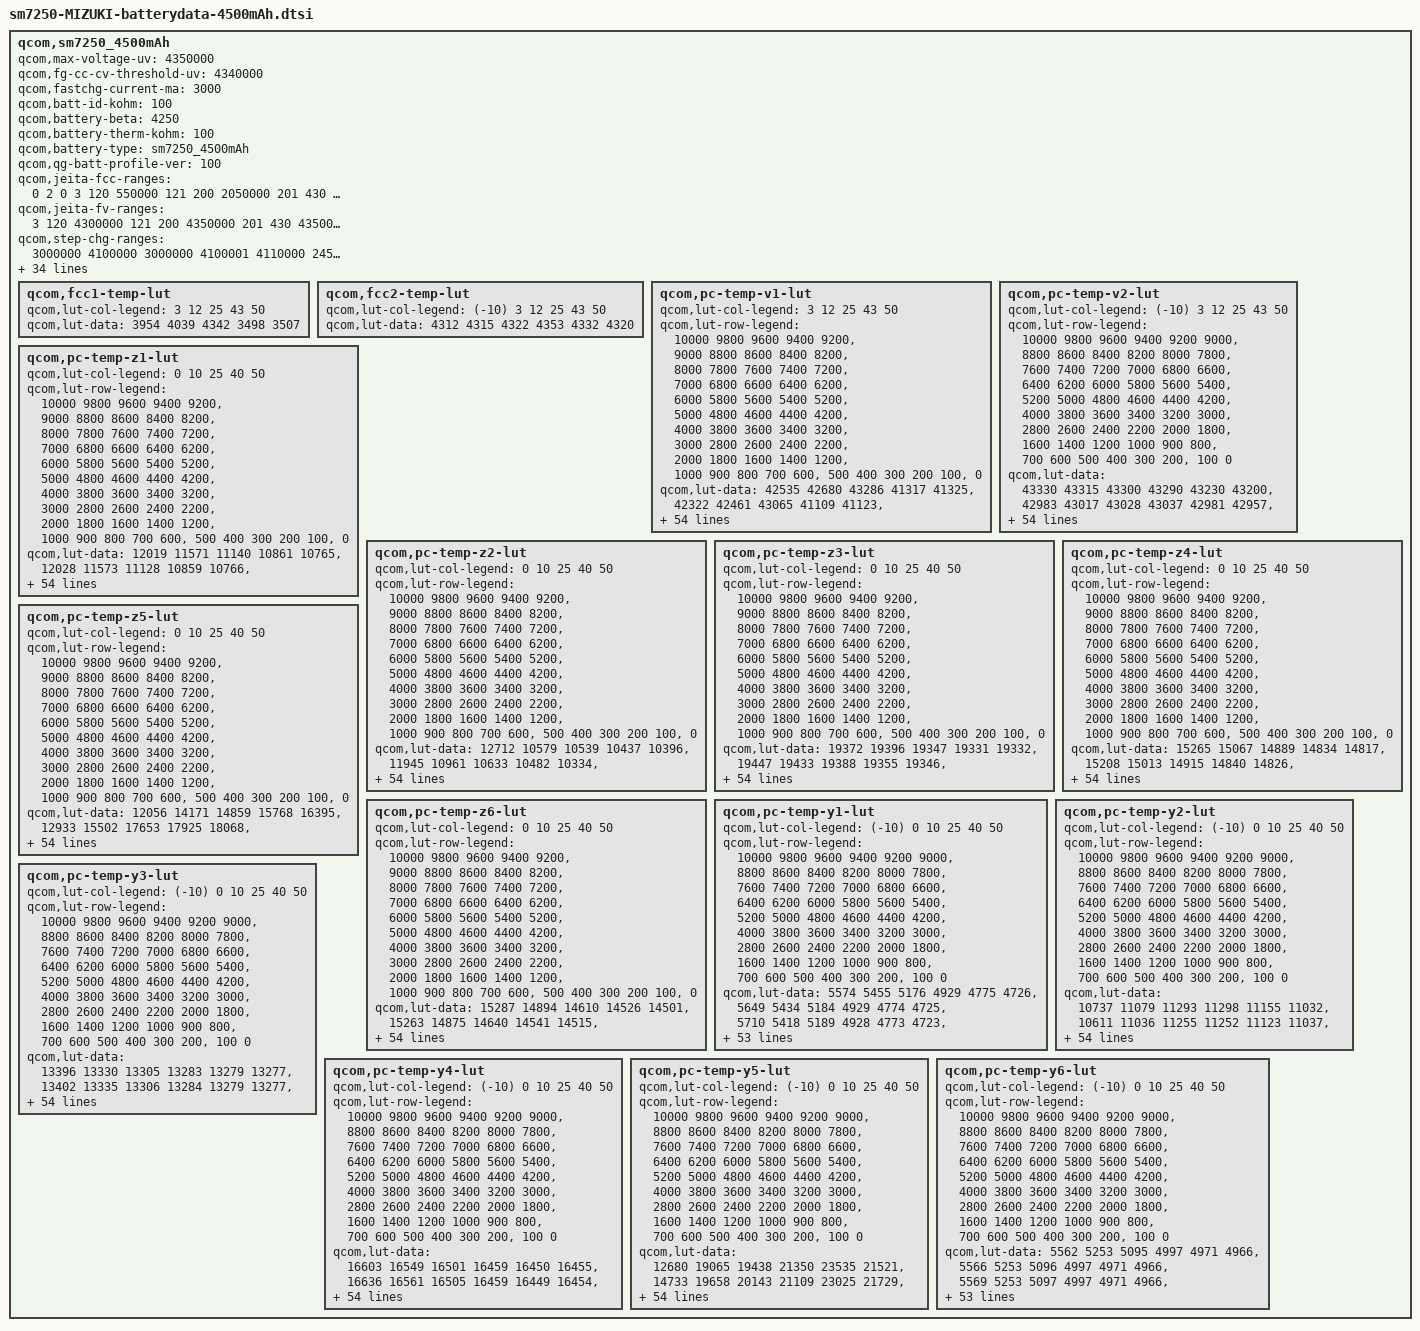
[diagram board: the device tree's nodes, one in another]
/*
 * This software is contributed or developed by KYOCERA Corporation.
 * (C) 2020 KYOCERA Corporation
 *
 * This program is free software; you can redistribute it and/or modify
 * it under the terms of the GNU General Public License version 2 and
 * only version 2 as published by the Free Software Foundation.
 *
 * This program is distributed in the hope that it will be useful,
 * but WITHOUT ANY WARRANTY; without even the implied warranty of
 * MERCHANTABILITY or FITNESS FOR A PARTICULAR PURPOSE.  See the
 * GNU General Public License for more details.
 */

qcom,sm7250_4500mAh {
	qcom,max-voltage-uv = <4350000>;
	qcom,fg-cc-cv-threshold-uv = <4340000>;
	qcom,fastchg-current-ma = <3000>;
	qcom,batt-id-kohm = <100>;
	qcom,battery-beta = <4250>;
	qcom,battery-therm-kohm = <100>;
	qcom,battery-type = "sm7250_4500mAh";
	qcom,qg-batt-profile-ver = <100>;

	qcom,jeita-fcc-ranges = <0   2  0
				  3 120  550000
				121 200  2050000
				201 430  4200000
				431 500  2050000
				500 600  0>;

	qcom,jeita-fv-ranges = <3  120  4300000
				121 200  4350000
				201 430  4350000
				431 500  4150000>;

	qcom,step-chg-ranges = <3000000  4100000  3000000
				4100001  4110000  2450000
				4110001  4120000  2450000
				4120001  4130000  2450000
				4130001  4140000  2450000
				4140001  4150000  2450000
				4150001  4350000  1200000>;
	qcom,step-chg-ranges-cool = <3000000  4350000  500000>;
	qcom,step-chg-ranges-weekcool = <3000000  4100000  2050000
				4100001  4150000  1650000
				4150001  4350000  1200000>;
	qcom,step-chg-ranges-normal = <3000000  4150000  3000000
				4150001  4250000  2450000
				4250001  4350000  1200000>;
	qcom,step-chg-ranges-warm = <3000000  4350000  2050000>;
	qcom,step-chg-temp-thresh = <30 100 200 430>;
	qcom,ocv-based-step-chg;

	/* COOL = 12 DegC, WARM = 43 DegC */
	qcom,jeita-soft-thresholds = <0x4A2A 0x22B8>;
	/* COLD = 3 DegC, HOT = 50 DegC */
	qcom,jeita-hard-thresholds = <0x5571 0x1C22>;
	/* COOL hys = 14 DegC, WARM hys = 41 DegC */
	qcom,jeita-soft-hys-thresholds = <0x477C 0x24CF>;
	qcom,jeita-soft-fcc-ua = <560000 2050000>;
	qcom,jeita-soft-fv-uv = <4300000 4150000>;

	oem,batt-capacity-mah = <4500>;
	oem,deterioration-thresh-good = <75>;
	oem,deterioration-thresh-norm = <50>;
	oem,deterioration-thresh-normtogood = <85>;
	oem,deterioration-thresh-deadtonorm = <60>;
	oem,cycle-count-thresh = <50 100 200 400 600>;
	oem,cycle-count-voltage-comp-mv = <40 80 120 160 200>;
	oem,cont-chg-thresh = <520000 840000 1200000 2200000 3300000>;
	oem,cont-chg-voltage-comp-mv = <40 80 120 160 200>;
	oem,batt-temp-thresh = <(-1250) 300 320 340 360 380 400 420 440 460>;
	oem,cont-chg-factor = <29 42 60 86 124 180 261 378 549 783>;
	oem,cont-chg-factor-batt-care = <15 21 30 43 62 90 131 189 275 392>;
	oem,batt-care-max-voltage-uv = <4200000>;

	qcom,fcc1-temp-lut {
		qcom,lut-col-legend = <3 12 25 43 50>;
		qcom,lut-data = <3954 4039 4342 3498 3507>;
	};

	qcom,fcc2-temp-lut {
		qcom,lut-col-legend = <(-10) 3 12 25 43 50>;
		qcom,lut-data = <4312 4315 4322 4353 4332 4320>;
	};

	qcom,pc-temp-v1-lut {
		qcom,lut-col-legend = <3 12 25 43 50>;
		qcom,lut-row-legend = <10000 9800 9600 9400 9200>,
			<9000 8800 8600 8400 8200>,
			<8000 7800 7600 7400 7200>,
			<7000 6800 6600 6400 6200>,
			<6000 5800 5600 5400 5200>,
			<5000 4800 4600 4400 4200>,
			<4000 3800 3600 3400 3200>,
			<3000 2800 2600 2400 2200>,
			<2000 1800 1600 1400 1200>,
			<1000 900 800 700 600>,
			<500 400 300 200 100>,
			<0>;
		qcom,lut-data = <42535 42680 43286 41317 41325>,
			<42322 42461 43065 41109 41123>,
			<42100 42242 42845 40894 40913>,
			<41869 42021 42626 40675 40696>,
			<41647 41799 42408 40456 40479>,
			<41441 41582 42190 40239 40263>,
			<41247 41372 41974 40023 40047>,
			<41057 41168 41759 39809 39832>,
			<40871 40970 41548 39596 39618>,
			<40691 40775 41342 39387 39407>,
			<40517 40586 41143 39182 39199>,
			<40350 40405 40949 38981 38996>,
			<40174 40231 40756 38786 38801>,
			<39959 40051 40567 38596 38612>,
			<39718 39843 40384 38413 38429>,
			<39528 39635 40206 38237 38253>,
			<39409 39467 40037 38068 38082>,
			<39305 39346 39882 37907 37918>,
			<39159 39217 39742 37760 37768>,
			<38950 39006 39580 37601 37609>,
			<38737 38716 39348 37389 37403>,
			<38562 38506 39101 37144 37160>,
			<38402 38403 38936 36959 36970>,
			<38290 38325 38823 36829 36838>,
			<38230 38241 38723 36719 36726>,
			<38186 38155 38621 36615 36620>,
			<38136 38073 38524 36519 36521>,
			<38077 37999 38438 36432 36431>,
			<38018 37929 38362 36354 36350>,
			<37963 37866 38294 36282 36275>,
			<37912 37810 38233 36215 36205>,
			<37865 37759 38178 36152 36138>,
			<37822 37716 38128 36094 36076>,
			<37783 37680 38084 36041 36015>,
			<37746 37646 38044 35991 35958>,
			<37713 37613 38004 35940 35898>,
			<37678 37581 37966 35889 35838>,
			<37626 37537 37921 35830 35770>,
			<37545 37458 37851 35751 35686>,
			<37446 37357 37757 35652 35585>,
			<37336 37249 37654 35545 35475>,
			<37205 37128 37535 35428 35353>,
			<37054 36987 37399 35296 35217>,
			<36900 36826 37238 35140 35056>,
			<36804 36695 37117 35030 34959>,
			<36721 36628 37046 34968 34906>,
			<36694 36605 37026 34945 34885>,
			<36670 36589 37008 34929 34869>,
			<36642 36572 36987 34910 34847>,
			<36562 36501 36915 34822 34746>,
			<36306 36236 36629 34500 34406>,
			<35850 35786 36179 34054 33964>,
			<35277 35214 35607 33483 33392>,
			<34511 34446 34834 32709 32618>,
			<33287 33229 33628 31513 31421>,
			<30000 30000 30000 30000 30000>;
	};

	qcom,pc-temp-v2-lut {
		qcom,lut-col-legend = <(-10) 3 12 25 43 50>;
		qcom,lut-row-legend = <10000 9800 9600 9400 9200 9000>,
			<8800 8600 8400 8200 8000 7800>,
			<7600 7400 7200 7000 6800 6600>,
			<6400 6200 6000 5800 5600 5400>,
			<5200 5000 4800 4600 4400 4200>,
			<4000 3800 3600 3400 3200 3000>,
			<2800 2600 2400 2200 2000 1800>,
			<1600 1400 1200 1000 900 800>,
			<700 600 500 400 300 200>,
			<100 0>;
		qcom,lut-data = <43330 43315 43300 43290 43230 43200>,
			<42983 43017 43028 43037 42981 42957>,
			<42667 42739 42769 42794 42740 42722>,
			<42386 42483 42526 42559 42508 42493>,
			<42138 42248 42300 42335 42286 42272>,
			<41905 42026 42081 42115 42068 42055>,
			<41664 41808 41864 41896 41851 41839>,
			<41428 41597 41652 41681 41637 41624>,
			<41229 41392 41444 41469 41426 41414>,
			<41085 41188 41236 41258 41218 41206>,
			<40947 40990 41033 41053 41014 41002>,
			<40762 40800 40846 40858 40817 40805>,
			<40524 40620 40674 40672 40625 40612>,
			<40275 40434 40492 40486 40438 40426>,
			<40025 40228 40275 40290 40255 40245>,
			<39774 40013 40048 40098 40078 40070>,
			<39551 39808 39863 39929 39912 39904>,
			<39354 39612 39718 39786 39765 39754>,
			<39170 39419 39569 39630 39608 39596>,
			<38992 39218 39363 39425 39405 39397>,
			<38822 39015 39119 39194 39172 39169>,
			<38668 38837 38916 38993 38972 38971>,
			<38524 38689 38760 38817 38806 38807>,
			<38399 38558 38627 38663 38661 38662>,
			<38308 38441 38511 38540 38540 38541>,
			<38237 38337 38408 38436 38437 38435>,
			<38177 38243 38315 38343 38343 38340>,
			<38120 38154 38227 38257 38254 38250>,
			<38067 38073 38146 38179 38172 38167>,
			<38019 38011 38071 38104 38099 38092>,
			<37974 37962 38001 38035 38034 38026>,
			<37931 37920 37939 37969 37970 37962>,
			<37888 37886 37888 37909 37907 37898>,
			<37846 37856 37845 37852 37844 37834>,
			<37802 37825 37803 37793 37771 37758>,
			<37759 37793 37763 37732 37682 37653>,
			<37713 37756 37721 37667 37588 37540>,
			<37658 37710 37668 37596 37504 37446>,
			<37590 37648 37600 37518 37425 37365>,
			<37510 37572 37520 37434 37342 37283>,
			<37410 37464 37421 37345 37254 37194>,
			<37291 37326 37305 37246 37159 37098>,
			<37175 37190 37182 37125 37046 36989>,
			<37062 37045 37039 36989 36906 36853>,
			<36966 36941 36948 36913 36836 36777>,
			<36894 36883 36903 36868 36808 36752>,
			<36854 36853 36880 36854 36792 36737>,
			<36808 36822 36858 36838 36776 36719>,
			<36738 36770 36818 36806 36741 36681>,
			<36584 36643 36710 36710 36609 36536>,
			<36286 36360 36406 36392 36271 36165>,
			<35832 35892 35901 35911 35780 35674>,
			<35222 35255 35254 35291 35149 35039>,
			<34365 34370 34366 34451 34296 34185>,
			<32940 32942 33061 33250 33114 32963>,
			<29519 29510 29510 29509 30000 30000>;
	};

	qcom,pc-temp-z1-lut {
		qcom,lut-col-legend = <0 10 25 40 50>;
		qcom,lut-row-legend = <10000 9800 9600 9400 9200>,
			<9000 8800 8600 8400 8200>,
			<8000 7800 7600 7400 7200>,
			<7000 6800 6600 6400 6200>,
			<6000 5800 5600 5400 5200>,
			<5000 4800 4600 4400 4200>,
			<4000 3800 3600 3400 3200>,
			<3000 2800 2600 2400 2200>,
			<2000 1800 1600 1400 1200>,
			<1000 900 800 700 600>,
			<500 400 300 200 100>,
			<0>;
		qcom,lut-data = <12019 11571 11140 10861 10765>,
			<12028 11573 11128 10859 10766>,
			<12010 11574 11115 10854 10764>,
			<11978 11571 11102 10846 10761>,
			<11952 11558 11092 10839 10758>,
			<11939 11542 11084 10835 10756>,
			<11930 11523 11077 10831 10753>,
			<11924 11503 11072 10828 10751>,
			<11920 11491 11067 10827 10749>,
			<11917 11485 11064 10825 10748>,
			<11913 11481 11063 10823 10747>,
			<11900 11475 11061 10822 10746>,
			<11886 11468 11057 10822 10745>,
			<11872 11463 11053 10821 10745>,
			<11857 11459 11051 10821 10745>,
			<11850 11455 11052 10822 10745>,
			<11852 11455 11052 10823 10746>,
			<11857 11467 11053 10824 10746>,
			<11862 11479 11055 10825 10747>,
			<11878 11484 11056 10826 10748>,
			<11891 11489 11057 10827 10749>,
			<11886 11491 11059 10829 10750>,
			<11867 11483 11061 10830 10752>,
			<11856 11472 11068 10833 10754>,
			<11859 11472 11075 10835 10757>,
			<11864 11482 11082 10839 10760>,
			<11865 11493 11089 10842 10763>,
			<11861 11494 11093 10845 10766>,
			<11857 11495 11096 10848 10769>,
			<11859 11495 11099 10850 10771>,
			<11867 11498 11104 10853 10773>,
			<11876 11503 11110 10856 10776>,
			<11881 11509 11117 10859 10778>,
			<11887 11522 11124 10863 10781>,
			<11891 11533 11130 10867 10785>,
			<11903 11537 11133 10872 10787>,
			<11918 11540 11135 10877 10790>,
			<11923 11541 11137 10881 10793>,
			<11923 11544 11142 10886 10796>,
			<11921 11548 11148 10890 10799>,
			<11918 11549 11155 10894 10802>,
			<11913 11550 11162 10898 10804>,
			<11922 11551 11170 10902 10806>,
			<11941 11556 11178 10906 10808>,
			<11945 11565 11179 10909 10810>,
			<11951 11560 11182 10910 10811>,
			<11925 11559 11181 10912 10812>,
			<11932 11566 11176 10915 10814>,
			<11930 11560 11183 10918 10817>,
			<11935 11559 11187 10922 10822>,
			<11960 11564 11193 10925 10826>,
			<11964 11563 11199 10931 10831>,
			<11971 11592 11217 10938 10837>,
			<11992 11606 11225 10948 10845>,
			<11992 11606 11225 10948 10845>,
			<11992 11606 11225 10948 10845>;
	};

	qcom,pc-temp-z2-lut {
		qcom,lut-col-legend = <0 10 25 40 50>;
		qcom,lut-row-legend = <10000 9800 9600 9400 9200>,
			<9000 8800 8600 8400 8200>,
			<8000 7800 7600 7400 7200>,
			<7000 6800 6600 6400 6200>,
			<6000 5800 5600 5400 5200>,
			<5000 4800 4600 4400 4200>,
			<4000 3800 3600 3400 3200>,
			<3000 2800 2600 2400 2200>,
			<2000 1800 1600 1400 1200>,
			<1000 900 800 700 600>,
			<500 400 300 200 100>,
			<0>;
		qcom,lut-data = <12712 10579 10539 10437 10396>,
			<11945 10961 10633 10482 10334>,
			<11307 11143 10622 10469 10314>,
			<10707 11061 10602 10446 10300>,
			<10388 10723 10573 10416 10288>,
			<10357 10503 10524 10363 10258>,
			<10341 10478 10496 10316 10228>,
			<10331 10460 10498 10296 10227>,
			<10322 10455 10505 10282 10239>,
			<10316 10465 10506 10277 10252>,
			<10335 10480 10505 10285 10263>,
			<10425 10555 10503 10294 10273>,
			<10496 10752 10497 10303 10281>,
			<10476 10856 10489 10312 10290>,
			<10423 10735 10485 10317 10298>,
			<10398 10553 10488 10320 10310>,
			<10393 10510 10494 10324 10326>,
			<10388 10517 10503 10331 10337>,
			<10388 10526 10522 10357 10345>,
			<10395 10537 10545 10389 10356>,
			<10402 10553 10580 10446 10409>,
			<10403 10561 10614 10525 10511>,
			<10402 10556 10622 10552 10548>,
			<10402 10548 10619 10558 10487>,
			<10410 10547 10611 10552 10393>,
			<10425 10554 10598 10497 10310>,
			<10435 10559 10575 10377 10221>,
			<10441 10549 10549 10281 10174>,
			<10445 10524 10514 10214 10157>,
			<10448 10513 10488 10168 10144>,
			<10450 10521 10490 10168 10146>,
			<10452 10535 10505 10200 10166>,
			<10457 10551 10525 10237 10193>,
			<10464 10570 10557 10272 10234>,
			<10471 10586 10595 10310 10292>,
			<10477 10596 10620 10350 10344>,
			<10483 10604 10640 10392 10394>,
			<10491 10615 10661 10436 10433>,
			<10501 10643 10696 10491 10454>,
			<10507 10669 10736 10548 10471>,
			<10501 10670 10744 10563 10474>,
			<10488 10659 10725 10530 10451>,
			<10489 10658 10718 10504 10429>,
			<10536 10673 10728 10492 10420>,
			<14837 10777 10734 10461 10397>,
			<16165 10769 10706 10489 10353>,
			<20813 10765 10705 10499 10370>,
			<19221 10777 10695 10512 10391>,
			<19301 10836 10708 10603 10483>,
			<20631 10928 10747 10632 10516>,
			<19576 11039 10691 10375 10260>,
			<18100 11075 10602 10301 10183>,
			<15575 11073 10527 10258 10149>,
			<14743 11024 10476 10202 10085>,
			<14743 11024 10476 10202 10085>,
			<14743 11024 10476 10202 10085>;
	};

	qcom,pc-temp-z3-lut {
		qcom,lut-col-legend = <0 10 25 40 50>;
		qcom,lut-row-legend = <10000 9800 9600 9400 9200>,
			<9000 8800 8600 8400 8200>,
			<8000 7800 7600 7400 7200>,
			<7000 6800 6600 6400 6200>,
			<6000 5800 5600 5400 5200>,
			<5000 4800 4600 4400 4200>,
			<4000 3800 3600 3400 3200>,
			<3000 2800 2600 2400 2200>,
			<2000 1800 1600 1400 1200>,
			<1000 900 800 700 600>,
			<500 400 300 200 100>,
			<0>;
		qcom,lut-data = <19372 19396 19347 19331 19332>,
			<19447 19433 19388 19355 19346>,
			<19512 19460 19402 19369 19358>,
			<19576 19476 19410 19379 19368>,
			<19608 19490 19413 19382 19372>,
			<19609 19497 19415 19382 19371>,
			<19609 19497 19416 19381 19371>,
			<19609 19496 19414 19378 19370>,
			<19606 19495 19409 19374 19368>,
			<19603 19491 19404 19370 19366>,
			<19600 19486 19399 19367 19364>,
			<19597 19484 19394 19364 19363>,
			<19594 19482 19391 19362 19360>,
			<19591 19480 19389 19361 19356>,
			<19586 19477 19387 19359 19352>,
			<19581 19471 19385 19357 19350>,
			<19570 19467 19384 19355 19347>,
			<19559 19461 19382 19352 19345>,
			<19558 19457 19378 19348 19341>,
			<19571 19459 19377 19345 19338>,
			<19583 19468 19379 19347 19340>,
			<19582 19472 19383 19354 19346>,
			<19575 19464 19384 19362 19355>,
			<19569 19453 19384 19381 19372>,
			<19563 19453 19384 19398 19389>,
			<19558 19471 19396 19399 19390>,
			<19557 19487 19420 19396 19387>,
			<19562 19489 19428 19392 19382>,
			<19568 19490 19424 19386 19376>,
			<19568 19490 19418 19378 19369>,
			<19568 19486 19413 19372 19363>,
			<19566 19479 19406 19368 19358>,
			<19563 19473 19400 19363 19353>,
			<19558 19468 19395 19358 19348>,
			<19554 19463 19389 19352 19342>,
			<19551 19460 19385 19348 19339>,
			<19548 19456 19382 19345 19337>,
			<19544 19453 19379 19343 19335>,
			<19539 19450 19376 19345 19337>,
			<19535 19447 19373 19349 19341>,
			<19532 19443 19372 19351 19345>,
			<19529 19439 19371 19352 19347>,
			<19524 19436 19370 19353 19349>,
			<19511 19431 19370 19354 19352>,
			<19262 19414 19360 19350 19348>,
			<19257 19400 19352 19334 19339>,
			<19256 19399 19346 19332 19331>,
			<19257 19388 19345 19329 19326>,
			<19256 19362 19343 19318 19314>,
			<19256 19352 19339 19319 19316>,
			<19256 19345 19352 19348 19340>,
			<19256 19332 19363 19351 19341>,
			<19257 19330 19361 19350 19341>,
			<19257 19328 19363 19354 19347>,
			<19257 19328 19363 19354 19347>,
			<19257 19328 19363 19354 19347>;
	};

	qcom,pc-temp-z4-lut {
		qcom,lut-col-legend = <0 10 25 40 50>;
		qcom,lut-row-legend = <10000 9800 9600 9400 9200>,
			<9000 8800 8600 8400 8200>,
			<8000 7800 7600 7400 7200>,
			<7000 6800 6600 6400 6200>,
			<6000 5800 5600 5400 5200>,
			<5000 4800 4600 4400 4200>,
			<4000 3800 3600 3400 3200>,
			<3000 2800 2600 2400 2200>,
			<2000 1800 1600 1400 1200>,
			<1000 900 800 700 600>,
			<500 400 300 200 100>,
			<0>;
		qcom,lut-data = <15265 15067 14889 14834 14817>,
			<15208 15013 14915 14840 14826>,
			<15142 14963 14883 14828 14818>,
			<15067 14918 14834 14796 14792>,
			<15000 14874 14801 14769 14766>,
			<14946 14837 14774 14745 14742>,
			<14900 14806 14752 14726 14723>,
			<14863 14779 14735 14718 14715>,
			<14834 14760 14721 14713 14711>,
			<14809 14745 14714 14708 14707>,
			<14779 14732 14709 14704 14703>,
			<14742 14717 14705 14699 14699>,
			<14720 14699 14701 14693 14696>,
			<14734 14690 14696 14688 14692>,
			<14769 14702 14691 14683 14688>,
			<14786 14721 14685 14677 14684>,
			<14765 14723 14681 14673 14680>,
			<14735 14708 14679 14672 14678>,
			<14732 14694 14678 14672 14676>,
			<14774 14729 14678 14673 14675>,
			<14826 14833 14733 14703 14698>,
			<14867 14887 14811 14771 14759>,
			<14907 14880 14826 14793 14783>,
			<14926 14865 14816 14764 14755>,
			<14910 14844 14800 14728 14718>,
			<14876 14810 14772 14713 14704>,
			<14849 14779 14735 14703 14697>,
			<14826 14763 14717 14697 14691>,
			<14806 14751 14711 14693 14687>,
			<14792 14746 14707 14689 14683>,
			<14782 14745 14705 14685 14679>,
			<14774 14744 14703 14681 14674>,
			<14769 14743 14702 14679 14671>,
			<14765 14741 14701 14678 14670>,
			<14761 14738 14701 14678 14669>,
			<14756 14733 14700 14678 14669>,
			<14751 14727 14699 14679 14671>,
			<14748 14725 14698 14679 14674>,
			<14747 14727 14701 14682 14678>,
			<14745 14729 14705 14688 14682>,
			<14739 14725 14705 14689 14683>,
			<14727 14711 14695 14681 14677>,
			<14716 14702 14689 14677 14675>,
			<14710 14696 14688 14682 14687>,
			<14900 14673 14674 14666 14668>,
			<14893 14666 14666 14660 14648>,
			<14886 14655 14658 14652 14642>,
			<14879 14658 14641 14638 14631>,
			<14872 14677 14632 14631 14625>,
			<14871 14690 14641 14630 14623>,
			<14878 14712 14651 14641 14651>,
			<14883 14730 14644 14645 14655>,
			<14886 14733 14648 14648 14657>,
			<14887 14736 14649 14646 14654>,
			<14887 14736 14649 14646 14654>,
			<14887 14736 14649 14646 14654>;
	};

	qcom,pc-temp-z5-lut {
		qcom,lut-col-legend = <0 10 25 40 50>;
		qcom,lut-row-legend = <10000 9800 9600 9400 9200>,
			<9000 8800 8600 8400 8200>,
			<8000 7800 7600 7400 7200>,
			<7000 6800 6600 6400 6200>,
			<6000 5800 5600 5400 5200>,
			<5000 4800 4600 4400 4200>,
			<4000 3800 3600 3400 3200>,
			<3000 2800 2600 2400 2200>,
			<2000 1800 1600 1400 1200>,
			<1000 900 800 700 600>,
			<500 400 300 200 100>,
			<0>;
		qcom,lut-data = <12056 14171 14859 15768 16395>,
			<12933 15502 17653 17925 18068>,
			<14571 16779 18626 19276 19486>,
			<17239 18056 19284 20376 20748>,
			<19542 19813 20032 21313 21855>,
			<20766 21381 20752 22203 22841>,
			<21699 22540 21509 22827 23695>,
			<22732 23675 22605 23034 24383>,
			<23915 24960 23675 23153 24950>,
			<25169 26494 23917 23241 25534>,
			<26555 28045 23779 23487 26338>,
			<28243 29540 23682 23875 27110>,
			<29812 31112 24056 24404 27358>,
			<31115 31824 24996 25469 27394>,
			<32308 31108 25943 26646 27462>,
			<32747 29967 26886 27915 28241>,
			<31617 29805 27913 29094 29661>,
			<29984 31316 29135 29404 30166>,
			<31141 33481 30587 29354 30198>,
			<43044 35757 31238 29192 30161>,
			<54122 38424 29721 27594 28651>,
			<52513 39538 26786 24213 24768>,
			<44135 33359 23901 22893 23108>,
			<36892 24464 20384 23131 23692>,
			<32648 22682 18301 23635 24737>,
			<29402 24821 20602 24714 26158>,
			<28683 27821 25944 26785 28378>,
			<30126 31049 29605 27813 29457>,
			<32368 34860 31715 27689 29246>,
			<34658 37732 33407 27491 28938>,
			<37478 39903 34929 27935 29087>,
			<39712 41521 36281 29549 30235>,
			<41004 42074 37299 30801 31285>,
			<42023 42306 38153 31230 31752>,
			<42495 42319 38749 31503 32076>,
			<42637 41928 38626 31473 32103>,
			<42589 41084 37413 30892 31703>,
			<42152 40031 35731 30309 31144>,
			<40884 38400 33043 30021 30533>,
			<39513 36587 29699 29753 29855>,
			<38644 35243 28250 29674 29744>,
			<37852 34076 27835 29700 31496>,
			<36811 32847 27354 29696 33046>,
			<34593 31220 26645 29259 33840>,
			<12048 32945 25469 28215 33611>,
			<11608 28165 23302 21273 26855>,
			<11518 28971 22219 21244 23351>,
			<11473 25999 25432 22870 24476>,
			<11479 18285 27457 21754 23030>,
			<11529 16641 22781 22801 25962>,
			<11552 15431 22040 28902 26677>,
			<11506 14080 24914 26203 22698>,
			<11450 13840 22965 23076 20330>,
			<11406 13673 22300 22173 19429>,
			<11406 13673 22300 22173 19429>,
			<11406 13673 22300 22173 19429>;
	};

	qcom,pc-temp-z6-lut {
		qcom,lut-col-legend = <0 10 25 40 50>;
		qcom,lut-row-legend = <10000 9800 9600 9400 9200>,
			<9000 8800 8600 8400 8200>,
			<8000 7800 7600 7400 7200>,
			<7000 6800 6600 6400 6200>,
			<6000 5800 5600 5400 5200>,
			<5000 4800 4600 4400 4200>,
			<4000 3800 3600 3400 3200>,
			<3000 2800 2600 2400 2200>,
			<2000 1800 1600 1400 1200>,
			<1000 900 800 700 600>,
			<500 400 300 200 100>,
			<0>;
		qcom,lut-data = <15287 14894 14610 14526 14501>,
			<15263 14875 14640 14541 14515>,
			<15235 14855 14629 14538 14514>,
			<15201 14836 14613 14530 14509>,
			<15165 14813 14599 14522 14502>,
			<15128 14791 14586 14511 14492>,
			<15088 14771 14575 14501 14483>,
			<15055 14753 14564 14495 14478>,
			<15029 14738 14555 14490 14475>,
			<15006 14727 14548 14486 14472>,
			<14980 14718 14543 14482 14469>,
			<14948 14706 14539 14478 14466>,
			<14929 14694 14534 14474 14462>,
			<14930 14688 14530 14471 14459>,
			<14935 14690 14526 14468 14455>,
			<14936 14692 14523 14465 14451>,
			<14925 14692 14520 14462 14449>,
			<14909 14685 14518 14459 14446>,
			<14908 14678 14516 14457 14443>,
			<14934 14695 14516 14456 14441>,
			<14964 14744 14541 14471 14453>,
			<14982 14769 14578 14505 14484>,
			<14996 14763 14585 14517 14497>,
			<15002 14751 14581 14515 14495>,
			<14994 14744 14577 14511 14491>,
			<14978 14740 14574 14507 14487>,
			<14967 14737 14572 14503 14482>,
			<14959 14734 14569 14498 14478>,
			<14954 14731 14566 14492 14473>,
			<14950 14729 14562 14487 14468>,
			<14948 14727 14559 14483 14463>,
			<14946 14725 14555 14479 14459>,
			<14944 14724 14552 14476 14455>,
			<14943 14724 14550 14473 14451>,
			<14942 14723 14548 14470 14448>,
			<14943 14721 14547 14468 14447>,
			<14945 14720 14545 14467 14447>,
			<14948 14720 14544 14467 14447>,
			<14953 14723 14545 14469 14449>,
			<14958 14726 14547 14474 14453>,
			<14960 14725 14547 14476 14455>,
			<14961 14721 14544 14474 14455>,
			<14963 14719 14542 14473 14455>,
			<14964 14719 14544 14477 14462>,
			<14935 14707 14535 14469 14453>,
			<14933 14697 14527 14458 14439>,
			<14931 14694 14521 14453 14433>,
			<14930 14690 14514 14446 14425>,
			<14930 14688 14510 14438 14417>,
			<14935 14693 14512 14438 14417>,
			<14946 14704 14526 14460 14444>,
			<14955 14710 14531 14465 14449>,
			<14966 14717 14535 14468 14452>,
			<14980 14725 14540 14472 14456>,
			<14980 14725 14540 14472 14456>,
			<14980 14725 14540 14472 14456>;
	};

	qcom,pc-temp-y1-lut {
		qcom,lut-col-legend = <(-10) 0 10 25 40 50>;
		qcom,lut-row-legend = <10000 9800 9600 9400 9200 9000>,
			<8800 8600 8400 8200 8000 7800>,
			<7600 7400 7200 7000 6800 6600>,
			<6400 6200 6000 5800 5600 5400>,
			<5200 5000 4800 4600 4400 4200>,
			<4000 3800 3600 3400 3200 3000>,
			<2800 2600 2400 2200 2000 1800>,
			<1600 1400 1200 1000 900 800>,
			<700 600 500 400 300 200>,
			<100 0>;
		qcom,lut-data = <5574 5455 5176 4929 4775 4726>,
			<5649 5434 5184 4929 4774 4725>,
			<5710 5418 5189 4928 4773 4723>,
			<5756 5405 5191 4926 4773 4722>,
			<5786 5397 5192 4924 4772 4720>,
			<5798 5392 5190 4922 4771 4719>,
			<5787 5394 5186 4920 4770 4718>,
			<5758 5402 5179 4917 4769 4717>,
			<5746 5406 5176 4915 4768 4717>,
			<5763 5400 5174 4913 4767 4716>,
			<5783 5393 5171 4910 4766 4716>,
			<5785 5396 5167 4908 4765 4716>,
			<5776 5407 5158 4906 4764 4716>,
			<5771 5415 5153 4905 4763 4716>,
			<5779 5409 5157 4906 4763 4716>,
			<5795 5398 5163 4906 4764 4716>,
			<5798 5394 5164 4906 4764 4716>,
			<5782 5394 5158 4905 4763 4716>,
			<5768 5395 5152 4903 4763 4716>,
			<5769 5395 5154 4904 4764 4716>,
			<5775 5394 5158 4907 4765 4717>,
			<5778 5394 5160 4908 4766 4717>,
			<5783 5393 5161 4909 4767 4718>,
			<5789 5393 5162 4911 4767 4720>,
			<5785 5395 5161 4914 4768 4721>,
			<5764 5405 5158 4917 4770 4722>,
			<5748 5412 5156 4920 4773 4723>,
			<5751 5405 5157 4923 4775 4725>,
			<5756 5392 5160 4926 4777 4726>,
			<5762 5388 5163 4929 4779 4728>,
			<5775 5388 5170 4934 4782 4731>,
			<5787 5387 5175 4938 4784 4733>,
			<5782 5392 5174 4940 4787 4735>,
			<5766 5404 5171 4942 4789 4736>,
			<5755 5412 5170 4943 4791 4737>,
			<5749 5417 5171 4945 4794 4739>,
			<5741 5420 5174 4947 4795 4740>,
			<5737 5418 5178 4951 4797 4742>,
			<5734 5405 5184 4956 4798 4743>,
			<5732 5396 5188 4959 4800 4745>,
			<5732 5399 5188 4961 4802 4746>,
			<5732 5406 5186 4963 4804 4747>,
			<5730 5411 5188 4966 4807 4749>,
			<5721 5415 5200 4971 4810 4752>,
			<5717 5414 5207 4978 4813 4754>,
			<5736 5407 5209 4987 4815 4756>,
			<5742 5408 5214 4992 4815 4756>,
			<5740 5410 5226 4993 4815 4755>,
			<5740 5414 5225 4989 4815 4755>,
			<5762 5425 5216 4982 4814 4757>,
			<5769 5410 5221 4982 4817 4758>,
			<5777 5400 5218 4990 4821 4761>,
			<5795 5409 5237 4998 4825 4765>,
			<5838 5429 5236 5007 4831 4769>,
			<5838 5429 5236 5007 4831 4769>,
			<5838 5429 5236 5007 4831 4769>;
	};

	qcom,pc-temp-y2-lut {
		qcom,lut-col-legend = <(-10) 0 10 25 40 50>;
		qcom,lut-row-legend = <10000 9800 9600 9400 9200 9000>,
			<8800 8600 8400 8200 8000 7800>,
			<7600 7400 7200 7000 6800 6600>,
			<6400 6200 6000 5800 5600 5400>,
			<5200 5000 4800 4600 4400 4200>,
			<4000 3800 3600 3400 3200 3000>,
			<2800 2600 2400 2200 2000 1800>,
			<1600 1400 1200 1000 900 800>,
			<700 600 500 400 300 200>,
			<100 0>;
		qcom,lut-data = <10737 11079 11293 11298 11155 11032>,
			<10611 11036 11255 11252 11123 11037>,
			<10533 10994 11217 11202 11091 11032>,
			<10491 10954 11181 11152 11059 11021>,
			<10474 10919 11146 11110 11028 11004>,
			<10470 10892 11113 11079 11000 10983>,
			<10493 10871 11078 11060 10971 10951>,
			<10562 10854 11044 11045 10942 10906>,
			<10631 10845 11022 11036 10925 10881>,
			<10712 10839 11009 11029 10911 10873>,
			<10780 10836 11001 11024 10900 10867>,
			<10793 10864 11005 11023 10895 10857>,
			<10795 10988 11032 11021 10874 10844>,
			<10798 11085 11070 11023 10862 10837>,
			<10829 11111 11150 11040 10865 10840>,
			<10882 11127 11258 11072 10873 10847>,
			<10911 11143 11325 11123 10898 10854>,
			<10926 11160 11373 11223 10990 10864>,
			<10934 11172 11399 11308 11071 10879>,
			<10932 11168 11384 11350 11091 10941>,
			<10918 11158 11345 11380 11103 11064>,
			<10887 11154 11329 11382 11112 11116>,
			<10459 11174 11339 11329 11132 11114>,
			<9906 11202 11355 11278 11153 11111>,
			<9766 11217 11370 11283 11165 11113>,
			<9732 11226 11385 11311 11178 11129>,
			<9715 11236 11401 11347 11193 11148>,
			<9707 11260 11420 11411 11217 11171>,
			<9702 11290 11440 11473 11248 11196>,
			<9698 11301 11454 11491 11277 11217>,
			<9695 11293 11466 11498 11310 11233>,
			<9693 11281 11473 11500 11331 11248>,
			<9690 11265 11471 11497 11324 11265>,
			<9686 11231 11466 11493 11306 11282>,
			<9683 11197 11459 11493 11299 11288>,
			<9681 11168 11443 11494 11294 11261>,
			<9679 11135 11419 11494 11287 11219>,
			<9677 11100 11397 11480 11274 11193>,
			<9675 11062 11373 11446 11247 11173>,
			<9673 11002 11344 11414 11224 11154>,
			<9671 10783 11303 11388 11208 11135>,
			<9669 10404 11246 11361 11193 11116>,
			<9667 10113 11178 11333 11182 11090>,
			<9666 9879 11092 11302 11174 11051>,
			<9665 9760 11013 11243 11127 10983>,
			<9664 9727 10946 11190 10955 10842>,
			<9663 9716 10928 11189 10961 10827>,
			<9663 9708 10915 11194 11006 10829>,
			<9662 9703 10910 11243 11002 10833>,
			<9661 9697 10924 11234 10977 10843>,
			<9661 9691 10883 11169 10943 10835>,
			<9660 9686 10767 11104 10880 10759>,
			<9659 9678 10682 11045 10811 10667>,
			<9655 9673 10632 10956 10664 10542>,
			<9655 9673 10632 10956 10664 10542>,
			<9655 9673 10632 10956 10664 10542>;
	};

	qcom,pc-temp-y3-lut {
		qcom,lut-col-legend = <(-10) 0 10 25 40 50>;
		qcom,lut-row-legend = <10000 9800 9600 9400 9200 9000>,
			<8800 8600 8400 8200 8000 7800>,
			<7600 7400 7200 7000 6800 6600>,
			<6400 6200 6000 5800 5600 5400>,
			<5200 5000 4800 4600 4400 4200>,
			<4000 3800 3600 3400 3200 3000>,
			<2800 2600 2400 2200 2000 1800>,
			<1600 1400 1200 1000 900 800>,
			<700 600 500 400 300 200>,
			<100 0>;
		qcom,lut-data = <13396 13330 13305 13283 13279 13277>,
			<13402 13335 13306 13284 13279 13277>,
			<13409 13340 13307 13285 13279 13277>,
			<13415 13344 13309 13285 13279 13277>,
			<13421 13348 13311 13286 13280 13278>,
			<13426 13352 13313 13286 13280 13278>,
			<13429 13355 13315 13287 13281 13279>,
			<13432 13357 13318 13288 13282 13280>,
			<13433 13359 13320 13289 13283 13281>,
			<13420 13362 13321 13289 13283 13281>,
			<13405 13363 13322 13289 13284 13282>,
			<13404 13363 13325 13290 13284 13282>,
			<13409 13361 13328 13293 13285 13283>,
			<13412 13357 13330 13295 13285 13283>,
			<13409 13354 13325 13296 13285 13283>,
			<13401 13350 13317 13296 13285 13283>,
			<13393 13346 13315 13296 13286 13284>,
			<13386 13342 13316 13297 13288 13285>,
			<13380 13339 13316 13297 13291 13286>,
			<13375 13335 13314 13295 13289 13285>,
			<13370 13331 13309 13291 13283 13282>,
			<13365 13328 13305 13288 13280 13279>,
			<13359 13326 13302 13286 13279 13277>,
			<13351 13324 13300 13284 13278 13276>,
			<13339 13322 13300 13283 13278 13276>,
			<13318 13320 13299 13283 13278 13277>,
			<13306 13318 13299 13283 13278 13277>,
			<13316 13313 13299 13284 13278 13277>,
			<13338 13308 13298 13284 13277 13276>,
			<13355 13307 13297 13284 13277 13276>,
			<13365 13308 13297 13284 13277 13276>,
			<13375 13310 13297 13284 13277 13277>,
			<13384 13312 13297 13283 13278 13277>,
			<13394 13316 13298 13283 13278 13278>,
			<13404 13319 13299 13283 13278 13279>,
			<13419 13321 13299 13283 13277 13278>,
			<13436 13322 13299 13283 13277 13276>,
			<13454 13324 13300 13283 13277 13276>,
			<13472 13326 13300 13282 13278 13277>,
			<13492 13328 13300 13282 13278 13278>,
			<13519 13325 13301 13282 13279 13278>,
			<13551 13320 13301 13282 13280 13279>,
			<13590 13319 13301 13282 13280 13279>,
			<13639 13328 13302 13283 13277 13277>,
			<13697 13342 13304 13284 13277 13277>,
			<13771 13361 13310 13288 13284 13282>,
			<13812 13372 13314 13292 13287 13284>,
			<13867 13387 13320 13295 13289 13286>,
			<13892 13392 13323 13296 13288 13286>,
			<13890 13392 13324 13296 13285 13282>,
			<13933 13396 13322 13292 13284 13281>,
			<13990 13407 13322 13293 13285 13283>,
			<14106 13437 13327 13297 13287 13286>,
			<14468 13483 13338 13302 13292 13292>,
			<14468 13483 13338 13302 13292 13292>,
			<14468 13483 13338 13302 13292 13292>;
	};

	qcom,pc-temp-y4-lut {
		qcom,lut-col-legend = <(-10) 0 10 25 40 50>;
		qcom,lut-row-legend = <10000 9800 9600 9400 9200 9000>,
			<8800 8600 8400 8200 8000 7800>,
			<7600 7400 7200 7000 6800 6600>,
			<6400 6200 6000 5800 5600 5400>,
			<5200 5000 4800 4600 4400 4200>,
			<4000 3800 3600 3400 3200 3000>,
			<2800 2600 2400 2200 2000 1800>,
			<1600 1400 1200 1000 900 800>,
			<700 600 500 400 300 200>,
			<100 0>;
		qcom,lut-data = <16603 16549 16501 16459 16450 16455>,
			<16636 16561 16505 16459 16449 16454>,
			<16670 16572 16509 16460 16449 16454>,
			<16701 16583 16513 16461 16449 16453>,
			<16729 16592 16516 16462 16449 16453>,
			<16751 16601 16519 16463 16450 16453>,
			<16765 16607 16520 16464 16450 16452>,
			<16774 16613 16522 16465 16450 16452>,
			<16794 16619 16523 16467 16451 16452>,
			<16902 16626 16525 16471 16452 16452>,
			<17021 16635 16528 16476 16454 16453>,
			<17027 16659 16538 16480 16457 16455>,
			<16968 16715 16562 16484 16460 16457>,
			<16899 16749 16588 16489 16465 16460>,
			<16834 16746 16607 16494 16470 16463>,
			<16769 16738 16625 16500 16476 16468>,
			<16726 16726 16642 16513 16485 16476>,
			<16702 16707 16660 16541 16502 16491>,
			<16679 16681 16671 16560 16514 16502>,
			<16645 16642 16641 16550 16509 16499>,
			<16605 16589 16561 16526 16495 16486>,
			<16589 16553 16513 16503 16481 16475>,
			<16595 16535 16495 16476 16465 16463>,
			<16608 16521 16484 16458 16453 16453>,
			<16626 16512 16481 16457 16452 16452>,
			<16661 16504 16480 16458 16452 16452>,
			<16683 16499 16480 16459 16452 16452>,
			<16675 16499 16481 16463 16455 16453>,
			<16660 16498 16483 16468 16461 16458>,
			<16654 16498 16484 16473 16468 16463>,
			<16653 16501 16483 16478 16476 16470>,
			<16652 16505 16483 16482 16483 16478>,
			<16655 16509 16484 16486 16487 16485>,
			<16663 16516 16488 16489 16490 16492>,
			<16669 16524 16493 16489 16490 16494>,
			<16672 16537 16499 16483 16477 16480>,
			<16674 16551 16505 16475 16462 16462>,
			<16675 16557 16505 16468 16458 16459>,
			<16676 16562 16502 16462 16457 16460>,
			<16676 16564 16500 16460 16456 16462>,
			<16669 16564 16500 16465 16460 16467>,
			<16653 16565 16500 16469 16466 16474>,
			<16645 16564 16499 16466 16463 16473>,
			<16642 16561 16498 16457 16446 16447>,
			<16642 16560 16499 16459 16443 16439>,
			<16674 16579 16520 16476 16474 16489>,
			<16699 16596 16537 16497 16505 16523>,
			<16747 16633 16565 16522 16551 16571>,
			<16768 16652 16583 16538 16558 16583>,
			<16734 16654 16589 16544 16525 16531>,
			<16718 16650 16565 16487 16467 16465>,
			<16712 16636 16544 16479 16459 16462>,
			<16744 16643 16558 16491 16464 16462>,
			<16994 16676 16594 16521 16483 16475>,
			<16994 16676 16594 16521 16483 16475>,
			<16994 16676 16594 16521 16483 16475>;
	};

	qcom,pc-temp-y5-lut {
		qcom,lut-col-legend = <(-10) 0 10 25 40 50>;
		qcom,lut-row-legend = <10000 9800 9600 9400 9200 9000>,
			<8800 8600 8400 8200 8000 7800>,
			<7600 7400 7200 7000 6800 6600>,
			<6400 6200 6000 5800 5600 5400>,
			<5200 5000 4800 4600 4400 4200>,
			<4000 3800 3600 3400 3200 3000>,
			<2800 2600 2400 2200 2000 1800>,
			<1600 1400 1200 1000 900 800>,
			<700 600 500 400 300 200>,
			<100 0>;
		qcom,lut-data = <12680 19065 19438 21350 23535 21521>,
			<14733 19658 20143 21109 23025 21729>,
			<16011 20166 20649 20502 22489 21862>,
			<16697 20567 20981 19745 21972 21937>,
			<16976 20839 21167 19054 21523 21970>,
			<17030 20960 21233 18649 21186 21978>,
			<16595 20921 21162 18457 20994 21929>,
			<15498 20760 20934 18127 20856 21773>,
			<15032 20457 20639 17754 20631 21581>,
			<15386 18791 20106 16879 20101 20994>,
			<16123 16941 19424 16078 19449 20198>,
			<17711 16760 18799 16132 18863 19600>,
			<21397 17204 18172 16565 18108 19083>,
			<23676 17839 17588 16789 17347 18513>,
			<23369 18820 16966 16435 16481 17634>,
			<22814 20160 16430 15936 15707 16695>,
			<22680 21386 16676 15833 15584 16315>,
			<22966 22612 19768 15855 15905 16157>,
			<23277 23602 23010 15910 16434 16079>,
			<23397 24203 24290 17970 17445 16977>,
			<23475 24676 25164 21768 19089 19393>,
			<23370 24832 25396 22899 20411 20866>,
			<19641 24484 24356 22648 21534 21413>,
			<14560 23945 23098 22273 22297 21731>,
			<12821 23631 22957 21778 22276 21714>,
			<12062 23454 23160 21106 21821 21408>,
			<11743 23173 23298 20868 21181 20950>,
			<11934 21152 22988 21469 19854 19833>,
			<12369 17883 22462 22201 18364 18341>,
			<12710 16824 22335 22205 18050 17819>,
			<12972 17155 22507 21760 18114 17721>,
			<13181 17637 22776 21417 18224 17726>,
			<13299 18305 23208 21357 18648 18659>,
			<13372 19786 23840 21404 19587 20992>,
			<13487 20766 24089 21661 20485 22117>,
			<13878 21017 23730 22578 21456 22171>,
			<14319 21218 23173 23288 22158 22209>,
			<14402 21630 22790 22908 22218 22403>,
			<14391 22413 22498 21826 22199 23011>,
			<14370 22905 22153 20844 22173 23469>,
			<14275 21045 21496 19869 22428 23547>,
			<14066 17266 20775 19168 22836 23546>,
			<13842 15424 20627 19393 22447 23358>,
			<13547 14730 20861 20255 20037 22278>,
			<13425 14451 20902 19854 18997 20525>,
			<13540 14659 20305 18660 18896 16864>,
			<13598 14660 19892 18481 18010 15585>,
			<13643 14463 19293 18468 16164 14659>,
			<13765 14422 19380 19137 16189 14536>,
			<14267 14952 20901 19523 16734 15454>,
			<14544 15173 21374 20968 18913 17240>,
			<14440 15027 21557 22525 20005 17844>,
			<14468 14800 21065 23534 19936 18628>,
			<12837 14630 22097 24629 23958 23939>,
			<12837 14630 22097 24629 23958 23939>,
			<12837 14630 22097 24629 23958 23939>;
	};

	qcom,pc-temp-y6-lut {
		qcom,lut-col-legend = <(-10) 0 10 25 40 50>;
		qcom,lut-row-legend = <10000 9800 9600 9400 9200 9000>,
			<8800 8600 8400 8200 8000 7800>,
			<7600 7400 7200 7000 6800 6600>,
			<6400 6200 6000 5800 5600 5400>,
			<5200 5000 4800 4600 4400 4200>,
			<4000 3800 3600 3400 3200 3000>,
			<2800 2600 2400 2200 2000 1800>,
			<1600 1400 1200 1000 900 800>,
			<700 600 500 400 300 200>,
			<100 0>;
		qcom,lut-data = <5562 5253 5095 4997 4971 4966>,
			<5566 5253 5096 4997 4971 4966>,
			<5569 5253 5097 4997 4971 4966>,
			<5570 5253 5097 4997 4972 4966>,
			<5571 5253 5097 4998 4972 4967>,
			<5571 5253 5097 4998 4972 4967>,
			<5570 5253 5097 4998 4973 4967>,
			<5567 5251 5096 4999 4974 4968>,
			<5567 5249 5096 5000 4974 4968>,
			<5584 5248 5095 5001 4975 4969>,
			<5604 5248 5095 5002 4976 4969>,
			<5605 5250 5097 5004 4977 4970>,
			<5594 5261 5105 5007 4978 4971>,
			<5579 5268 5111 5009 4980 4973>,
			<5562 5266 5112 5011 4981 4974>,
			<5540 5262 5113 5013 4983 4975>,
			<5524 5257 5115 5016 4986 4977>,
			<5510 5250 5120 5025 4993 4983>,
			<5498 5241 5124 5030 4998 4987>,
			<5489 5227 5114 5026 4995 4985>,
			<5481 5209 5088 5016 4987 4978>,
			<5475 5198 5071 5007 4980 4973>,
			<5471 5192 5064 4998 4974 4968>,
			<5468 5188 5059 4992 4970 4965>,
			<5470 5186 5059 4992 4970 4964>,
			<5480 5184 5059 4992 4970 4964>,
			<5493 5182 5059 4993 4970 4965>,
			<5504 5182 5060 4995 4971 4965>,
			<5515 5182 5061 4997 4973 4966>,
			<5528 5183 5062 4999 4975 4968>,
			<5543 5188 5063 5001 4977 4970>,
			<5558 5195 5065 5003 4980 4973>,
			<5575 5205 5068 5004 4981 4976>,
			<5593 5217 5072 5005 4983 4978>,
			<5611 5230 5076 5005 4983 4979>,
			<5630 5243 5080 5004 4979 4975>,
			<5649 5257 5084 5002 4975 4969>,
			<5669 5271 5087 5001 4974 4968>,
			<5691 5286 5089 4999 4974 4969>,
			<5716 5300 5091 4999 4974 4970>,
			<5742 5312 5095 5001 4976 4972>,
			<5772 5323 5100 5003 4979 4975>,
			<5807 5338 5106 5003 4978 4975>,
			<5850 5360 5114 5003 4972 4967>,
			<5905 5388 5126 5005 4972 4965>,
			<5978 5427 5148 5015 4986 4983>,
			<6022 5452 5164 5026 4997 4995>,
			<6083 5485 5186 5035 5012 5010>,
			<6112 5499 5193 5039 5014 5013>,
			<6112 5502 5194 5041 5002 4996>,
			<6148 5516 5190 5021 4984 4976>,
			<6201 5538 5196 5021 4983 4977>,
			<6324 5590 5224 5029 4987 4980>,
			<6774 5658 5264 5044 4997 4990>,
			<6774 5658 5264 5044 4997 4990>,
			<6774 5658 5264 5044 4997 4990>;
	};
};
